# hyperlink register map
Vendor: Texas Instruments
Peripheral module from a debugger description file (folder Keystone2).
Registers are 32-bit, read-write, no defined reset value unless marked. A register's access mark holds for its fields unless they carry their own. Offsets are as the file gives them; lines under a group give offsets from that group; [hi:lo] are bit positions; {n}, {i} and the like mark numbered series; 'fields as' and 'values as' point back to an identical list; <NAME> marks a mode.

## HYPERLINK_1
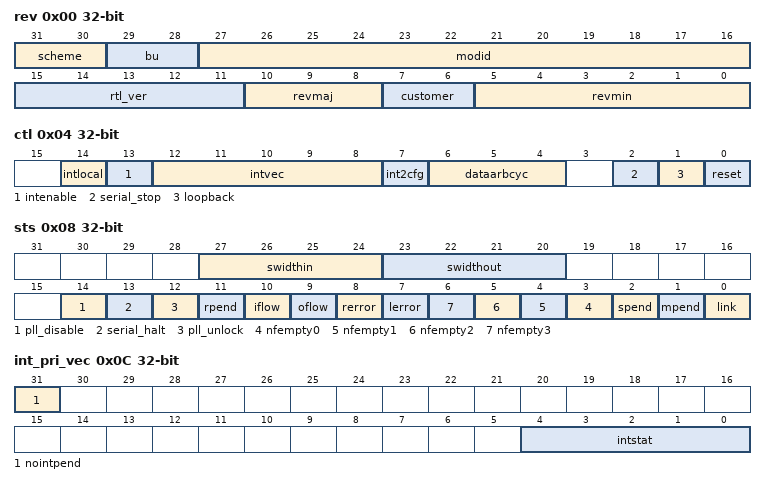
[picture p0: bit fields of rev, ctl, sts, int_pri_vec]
0x00 rev
  [31:30] scheme, [29:28] bu, [27:16] modid, [15:11] rtl_ver, [10:8] revmaj, [7:6] customer, [5:0] revmin
0x04 ctl
  [14] intlocal, [13] intenable, [12:8] intvec, [7] int2cfg, [6:4] dataarbcyc, [2] serial_stop, [1] loopback, [0] reset
0x08 sts
  [27:24] swidthin, [23:20] swidthout, [14] pll_disable, [13] serial_halt, [12] pll_unlock, [11] rpend, [10] iflow, [9] oflow, [8] rerror, [7] lerror, [n+3] nfempty{n} (n=0..3), [2] spend, [1] mpend, [0] link
0x0C int_pri_vec
  [31] nointpend, [4:0] intstat
0x10 int_clr
  [31:0] intclr
0x14 int_set
  [31:0] intset
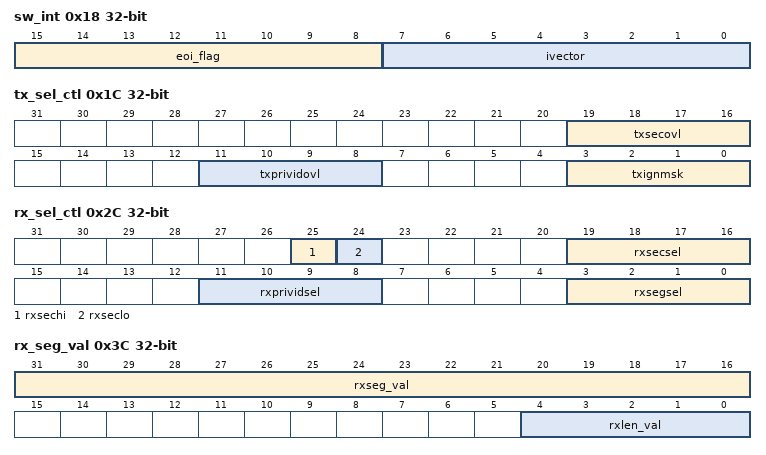
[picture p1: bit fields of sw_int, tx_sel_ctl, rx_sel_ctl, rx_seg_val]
0x18 sw_int
  [15:8] eoi_flag, [7:0] ivector
0x1C tx_sel_ctl
  [19:16] txsecovl, [11:8] txprividovl, [3:0] txignmsk
0x2C rx_sel_ctl
  [25] rxsechi, [24] rxseclo, [19:16] rxsecsel, [11:8] rxprividsel, [3:0] rxsegsel
0x30 rx_priv_idx
  [3:0] rxprivid_idx
0x34 rx_priv_val
  [3:0] rxprivid_val
0x38 rx_seg_idx
  [5:0] rxseg_idx
0x3C rx_seg_val
  [31:16] rxseg_val, [4:0] rxlen_val
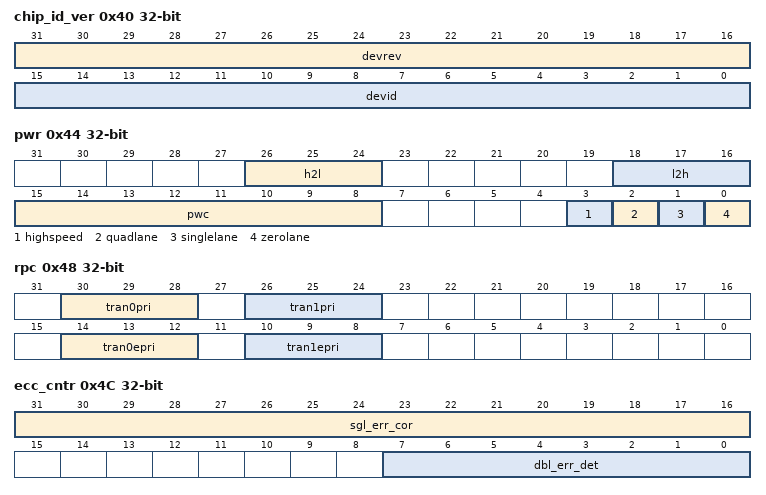
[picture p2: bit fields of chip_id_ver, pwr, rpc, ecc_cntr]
0x40 chip_id_ver
  [31:16] devrev, [15:0] devid
0x44 pwr
  [26:24] h2l, [18:16] l2h, [15:8] pwc, [3] highspeed, [2] quadlane, [1] singlelane, [0] zerolane
0x48 rpc
  [30:28] tran0pri, [26:24] tran1pri, [14:12] tran0epri, [10:8] tran1epri
0x4C ecc_cntr
  [31:16] sgl_err_cor, [7:0] dbl_err_det
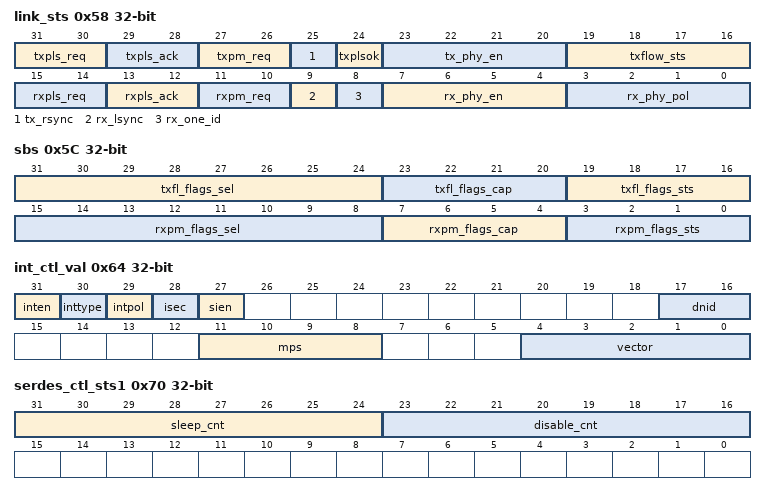
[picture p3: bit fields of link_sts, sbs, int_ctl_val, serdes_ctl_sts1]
0x58 link_sts
  [31:30] txpls_req, [29:28] txpls_ack, [27:26] txpm_req, [25] tx_rsync, [24] txplsok, [23:20] tx_phy_en, [19:16] txflow_sts, [15:14] rxpls_req, [13:12] rxpls_ack, [11:10] rxpm_req, [9] rx_lsync, [8] rx_one_id, [7:4] rx_phy_en, [3:0] rx_phy_pol
0x5C sbs
  [31:24] txfl_flags_sel, [23:20] txfl_flags_cap, [19:16] txfl_flags_sts, [15:8] rxpm_flags_sel, [7:4] rxpm_flags_cap, [3:0] rxpm_flags_sts
0x60 int_ctl_idx
  [7:0] icidx
0x64 int_ctl_val
  [31] inten, [30] inttype, [29] intpol, [28] isec, [27] sien, [17:16] dnid, [11:8] mps, [4:0] vector
0x68 int_ptr_idx
  [3:0] ipidx
0x6C int_ptr_val
  [31:2] intptr
0x70 serdes_ctl_sts1
  [31:24] sleep_cnt, [23:16] disable_cnt
0x74 serdes_ctl_sts2
  [31:16] s2ctl
0x78 serdes_ctl_sts3
  [31:16] s3ctl
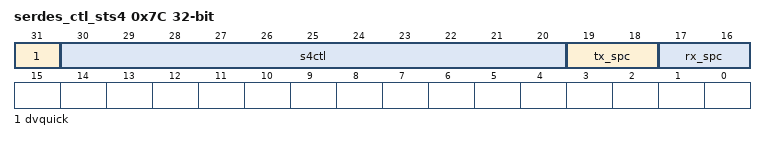
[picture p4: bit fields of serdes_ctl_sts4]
0x7C serdes_ctl_sts4
  [31] dvquick, [30:20] s4ctl, [19:18] tx_spc, [17:16] rx_spc
0x80 rem_regs — (1 of 32, stride 4)
  [31:0] remote_registers
